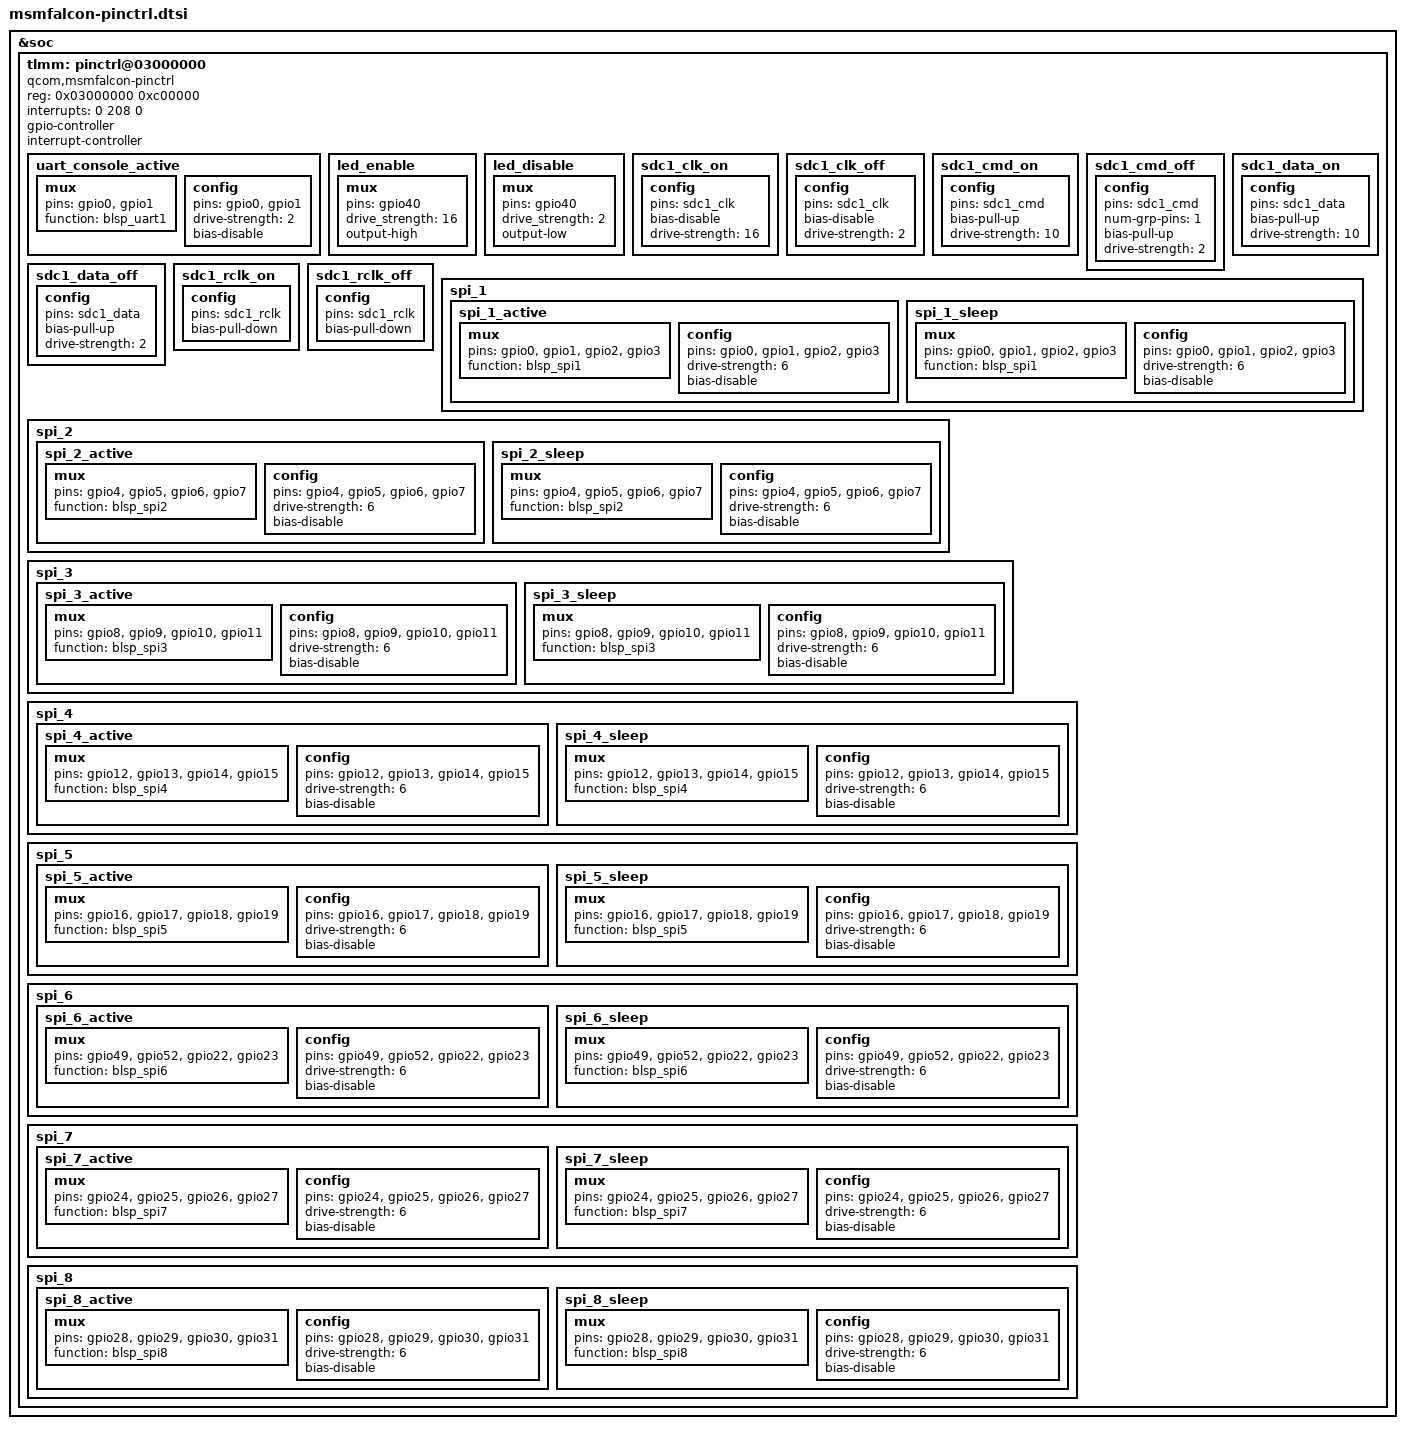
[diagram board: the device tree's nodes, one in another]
/* Copyright (c) 2016, The Linux Foundation. All rights reserved.
 *
 * This program is free software; you can redistribute it and/or modify
 * it under the terms of the GNU General Public License version 2 and
 * only version 2 as published by the Free Software Foundation.
 *
 * This program is distributed in the hope that it will be useful,
 * but WITHOUT ANY WARRANTY; without even the implied warranty of
 * MERCHANTABILITY or FITNESS FOR A PARTICULAR PURPOSE.  See the
 * GNU General Public License for more details.
 */

&soc {
	tlmm: pinctrl@03000000 {
		compatible = "qcom,msmfalcon-pinctrl";
		reg = <0x03000000 0xc00000>;
		interrupts = <0 208 0>;
		gpio-controller;
		#gpio-cells = <2>;
		interrupt-controller;
		#interrupt-cells = <2>;

		uart_console_active: uart_console_active {
			mux {
				pins = "gpio0", "gpio1";
				function = "blsp_uart1";
			};

			config {
				pins = "gpio0", "gpio1";
				drive-strength = <2>;
				bias-disable;
			};
		};

		led_enable: led_enable {
			mux {
				pins = "gpio40";
				drive_strength = <16>;
				output-high;
			};
		};

		led_disable: led_disable {
			mux {
				pins = "gpio40";
				drive_strength = <2>;
				output-low;
			};
		};

		/* SDC pin type */
		sdc1_clk_on: sdc1_clk_on {
			config {
				pins = "sdc1_clk";
				bias-disable;		/* NO pull */
				drive-strength = <16>;	/* 16 MA */
			};
		};

		sdc1_clk_off: sdc1_clk_off {
			config {
				pins = "sdc1_clk";
				bias-disable;		/* NO pull */
				drive-strength = <2>;	/* 2 MA */
			};
		};

		sdc1_cmd_on: sdc1_cmd_on {
			config {
				pins = "sdc1_cmd";
				bias-pull-up;		/* pull up */
				drive-strength = <10>;	/* 10 MA */
			};
		};

		sdc1_cmd_off: sdc1_cmd_off {
			config {
				pins = "sdc1_cmd";
				num-grp-pins = <1>;
				bias-pull-up;		/* pull up */
				drive-strength = <2>;	/* 2 MA */
			};
		};

		sdc1_data_on: sdc1_data_on {
			config {
				pins = "sdc1_data";
				bias-pull-up;		/* pull up */
				drive-strength = <10>;	/* 10 MA */
			};
		};

		sdc1_data_off: sdc1_data_off {
			config {
				pins = "sdc1_data";
				bias-pull-up;		/* pull up */
				drive-strength = <2>;	/* 2 MA */
			};
		};

		sdc1_rclk_on: sdc1_rclk_on {
			config {
				pins = "sdc1_rclk";
				bias-pull-down; /* pull down */
			};
		};

		sdc1_rclk_off: sdc1_rclk_off {
			config {
				pins = "sdc1_rclk";
				bias-pull-down; /* pull down */
			};
		};

		/* SPI CONFIGURATION */
		spi_1 {
			spi_1_active: spi_1_active {
				mux {
					pins = "gpio0", "gpio1",
							"gpio2", "gpio3";
					function = "blsp_spi1";
				};

				config {
					pins = "gpio0", "gpio1",
							"gpio2", "gpio3";
					drive-strength = <6>;
					bias-disable;
				};
			};

			spi_1_sleep: spi_1_sleep {
				mux {
					pins = "gpio0", "gpio1",
							"gpio2", "gpio3";
					function = "blsp_spi1";
				};

				config {
					pins = "gpio0", "gpio1",
							"gpio2", "gpio3";
					drive-strength = <6>;
					bias-disable;
				};
			};
		};

		spi_2 {
			spi_2_active: spi_2_active {
				mux {
					pins = "gpio4", "gpio5",
							"gpio6", "gpio7";
					function = "blsp_spi2";
				};

				config {
					pins = "gpio4", "gpio5",
							"gpio6", "gpio7";
					drive-strength = <6>;
					bias-disable;
				};
			};

			spi_2_sleep: spi_2_sleep {
				mux {
					pins = "gpio4", "gpio5",
							"gpio6", "gpio7";
					function = "blsp_spi2";
				};

				config {
					pins = "gpio4", "gpio5",
							"gpio6", "gpio7";
					drive-strength = <6>;
					bias-disable;
				};
			};
		};

		spi_3 {
			spi_3_active: spi_3_active {
				mux {
					pins = "gpio8", "gpio9",
							"gpio10", "gpio11";
					function = "blsp_spi3";
				};

				config {
					pins = "gpio8", "gpio9",
							"gpio10", "gpio11";
					drive-strength = <6>;
					bias-disable;
				};
			};

			spi_3_sleep: spi_3_sleep {
				mux {
					pins = "gpio8", "gpio9",
							"gpio10", "gpio11";
					function = "blsp_spi3";
				};

				config {
					pins = "gpio8", "gpio9",
							"gpio10", "gpio11";
					drive-strength = <6>;
					bias-disable;
				};
			};
		};

		spi_4 {
			spi_4_active: spi_4_active {
				mux {
					pins = "gpio12", "gpio13",
							"gpio14", "gpio15";
					function = "blsp_spi4";
				};

				config {
					pins = "gpio12", "gpio13",
							"gpio14", "gpio15";
					drive-strength = <6>;
					bias-disable;
				};
			};

			spi_4_sleep: spi_4_sleep {
				mux {
					pins = "gpio12", "gpio13",
							"gpio14", "gpio15";
					function = "blsp_spi4";
				};

				config {
					pins = "gpio12", "gpio13",
							"gpio14", "gpio15";
					drive-strength = <6>;
					bias-disable;
				};
			};
		};

		spi_5 {
			spi_5_active: spi_5_active {
				mux {
					pins = "gpio16", "gpio17",
							"gpio18", "gpio19";
					function = "blsp_spi5";
				};

				config {
					pins = "gpio16", "gpio17",
							"gpio18", "gpio19";
					drive-strength = <6>;
					bias-disable;
				};
			};

			spi_5_sleep: spi_5_sleep {
				mux {
					pins = "gpio16", "gpio17",
							"gpio18", "gpio19";
					function = "blsp_spi5";
				};

				config {
					pins = "gpio16", "gpio17",
							"gpio18", "gpio19";
					drive-strength = <6>;
					bias-disable;
				};
			};
		};

		spi_6 {
			spi_6_active: spi_6_active {
				mux {
					pins = "gpio49", "gpio52",
							"gpio22", "gpio23";
					function = "blsp_spi6";
				};

				config {
					pins = "gpio49", "gpio52",
							"gpio22", "gpio23";
					drive-strength = <6>;
					bias-disable;
				};
			};

			spi_6_sleep: spi_6_sleep {
				mux {
					pins = "gpio49", "gpio52",
							"gpio22", "gpio23";
					function = "blsp_spi6";
				};

				config {
					pins = "gpio49", "gpio52",
							"gpio22", "gpio23";
					drive-strength = <6>;
					bias-disable;
				};
			};
		};

		spi_7 {
			spi_7_active: spi_7_active {
				mux {
					pins = "gpio24", "gpio25",
							"gpio26", "gpio27";
					function = "blsp_spi7";
				};

				config {
					pins = "gpio24", "gpio25",
							"gpio26", "gpio27";
					drive-strength = <6>;
					bias-disable;
				};
			};

			spi_7_sleep: spi_7_sleep {
				mux {
					pins = "gpio24", "gpio25",
							"gpio26", "gpio27";
					function = "blsp_spi7";
				};

				config {
					pins = "gpio24", "gpio25",
							"gpio26", "gpio27";
					drive-strength = <6>;
					bias-disable;
				};
			};
		};

		spi_8 {
			spi_8_active: spi_8_active {
				mux {
					pins = "gpio28", "gpio29",
							"gpio30", "gpio31";
					function = "blsp_spi8";
				};

				config {
					pins = "gpio28", "gpio29",
							"gpio30", "gpio31";
					drive-strength = <6>;
					bias-disable;
				};
			};

			spi_8_sleep: spi_8_sleep {
				mux {
					pins = "gpio28", "gpio29",
							"gpio30", "gpio31";
					function = "blsp_spi8";
				};

				config {
					pins = "gpio28", "gpio29",
							"gpio30", "gpio31";
					drive-strength = <6>;
					bias-disable;
				};
			};
		};
	};
};
